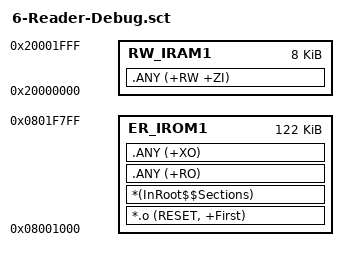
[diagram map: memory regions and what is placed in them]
; *************************************************************
; *** Scatter-Loading Description File generated by uVision ***
; *************************************************************

LR_IROM1 0x8001000 0x1e800  {    ; load region size_region                  Размер меньше размера памяти на 6 кБ - 4 на загрузчик и 2 на настройки в конце региона памяти
  ER_IROM1 0x8001000 0x1e800  {  ; load address = execution address
   *.o (RESET, +First)
   *(InRoot$$Sections)
   .ANY (+RO)
   .ANY (+XO)
  }
  RW_IRAM1 0x20000000 0x2000  {  ; RW data
   .ANY (+RW +ZI)
  }
}
